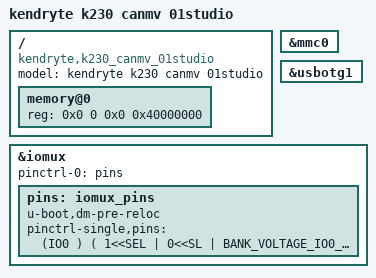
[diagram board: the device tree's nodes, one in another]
/* Copyright (c) 2023, Canaan Bright Sight Co., Ltd
 *
 * Redistribution and use in source and binary forms, with or without
 * modification, are permitted provided that the following conditions are met:
 * 1. Redistributions of source code must retain the above copyright
 * notice, this list of conditions and the following disclaimer.
 * 2. Redistributions in binary form must reproduce the above copyright
 * notice, this list of conditions and the following disclaimer in the
 * documentation and/or other materials provided with the distribution.
 *
 * THIS SOFTWARE IS PROVIDED BY THE COPYRIGHT HOLDERS AND
 * CONTRIBUTORS "AS IS" AND ANY EXPRESS OR IMPLIED WARRANTIES,
 * INCLUDING, BUT NOT LIMITED TO, THE IMPLIED WARRANTIES OF
 * MERCHANTABILITY AND FITNESS FOR A PARTICULAR PURPOSE ARE
 * DISCLAIMED. IN NO EVENT SHALL THE COPYRIGHT HOLDER OR
 * CONTRIBUTORS BE LIABLE FOR ANY DIRECT, INDIRECT, INCIDENTAL,
 * SPECIAL, EXEMPLARY, OR CONSEQUENTIAL DAMAGES (INCLUDING,
 * BUT NOT LIMITED TO, PROCUREMENT OF SUBSTITUTE GOODS OR
 * SERVICES; LOSS OF USE, DATA, OR PROFITS; OR BUSINESS
 * INTERRUPTION) HOWEVER CAUSED AND ON ANY THEORY OF LIABILITY,
 * WHETHER IN CONTRACT, STRICT LIABILITY, OR TORT (INCLUDING
 * NEGLIGENCE OR OTHERWISE) ARISING IN ANY WAY OUT OF THE USE
 * OF THIS SOFTWARE, EVEN IF ADVISED OF THE POSSIBILITY OF SUCH DAMAGE.
 */
/dts-v1/;
#include <dt-bindings/pinctrl/k230_evb.h>
#define BANK_VOLTAGE_IO0_IO1	 K230_MSC_1V8  /* fixed 1.8 V */
#define BANK_VOLTAGE_IO2_IO13	 K230_MSC_3V3  /* VDDIO_BANK0 */
#define BANK_VOLTAGE_IO14_IO25	 K230_MSC_1V8  /* VDDIO_BANK1 */
#define BANK_VOLTAGE_IO26_IO37	 K230_MSC_1V8  /* VDDIO_BANK2 */
#define BANK_VOLTAGE_IO38_IO49	 K230_MSC_3V3  /* VDDIO_BANK3 */
#define BANK_VOLTAGE_IO50_IO61	 K230_MSC_3V3  /* VDDIO_BANK4 */
#define BANK_VOLTAGE_IO62_IO63	 K230_MSC_1V8  /* VDDIO_BANK5 */
#include "k230.dtsi"

/ {
	model = "kendryte k230 canmv 01studio";
	compatible = "kendryte,k230_canmv_01studio";

	memory@0 {
		device_type = "memory";
		reg = <
				0x0 0 0x0 0x40000000
			  >;
	};
};

&mmc0 {
	status = "okay";
};
&usbotg1 {
	status = "okay";
};
&iomux {
	pinctrl-names = "default";
	pinctrl-0 = <&pins>;

	/*
	 * These voltage selections must match the board rails above; a mismatch can
	 * damage the SoC.  Use drive level 7 for driven signals and level 0 where the
	 * output buffer is disabled.  The K230 adaptation guide uses level 7 as its
	 * general-purpose setting for the dual-voltage pads.
	 */
	pins: iomux_pins {
		u-boot,dm-pre-reloc;
		pinctrl-single,pins = <

		/* Boot-mode straps: BOOT0 is pulled low and BOOT1 high externally. */
		(IO0 ) ( 1<<SEL | 0<<SL | BANK_VOLTAGE_IO0_IO1 <<MSC | 1<<IE | 0<<OE | 0<<PU | 0<<PD | 0<<DS | 1<<ST )
		(IO1 ) ( 1<<SEL | 0<<SL | BANK_VOLTAGE_IO0_IO1 <<MSC | 1<<IE | 0<<OE | 0<<PU | 0<<PD | 0<<DS | 1<<ST )

		/* IO2-IO8: unconnected; leave as high-impedance GPIOs. */
		(IO2 ) ( 0<<SEL | 0<<SL | BANK_VOLTAGE_IO2_IO13 <<MSC | 0<<IE | 0<<OE | 0<<PU | 0<<PD | 0<<DS | 0<<ST )
		(IO3 ) ( 0<<SEL | 0<<SL | BANK_VOLTAGE_IO2_IO13 <<MSC | 0<<IE | 0<<OE | 0<<PU | 0<<PD | 0<<DS | 0<<ST )
		(IO4 ) ( 0<<SEL | 0<<SL | BANK_VOLTAGE_IO2_IO13 <<MSC | 0<<IE | 0<<OE | 0<<PU | 0<<PD | 0<<DS | 0<<ST )
		(IO5 ) ( 0<<SEL | 0<<SL | BANK_VOLTAGE_IO2_IO13 <<MSC | 0<<IE | 0<<OE | 0<<PU | 0<<PD | 0<<DS | 0<<ST )
		(IO6 ) ( 0<<SEL | 0<<SL | BANK_VOLTAGE_IO2_IO13 <<MSC | 0<<IE | 0<<OE | 0<<PU | 0<<PD | 0<<DS | 0<<ST )
		(IO7 ) ( 0<<SEL | 0<<SL | BANK_VOLTAGE_IO2_IO13 <<MSC | 0<<IE | 0<<OE | 0<<PU | 0<<PD | 0<<DS | 0<<ST )
		(IO8 ) ( 0<<SEL | 0<<SL | BANK_VOLTAGE_IO2_IO13 <<MSC | 0<<IE | 0<<OE | 0<<PU | 0<<PD | 0<<DS | 0<<ST )

		/* Status LED, active high. */
		(IO9 ) ( 0<<SEL | 0<<SL | BANK_VOLTAGE_IO2_IO13 <<MSC | 0<<IE | 1<<OE | 0<<PU | 0<<PD | 7<<DS | 0<<ST )
		/* IO10: unconnected. */
		(IO10) ( 0<<SEL | 0<<SL | BANK_VOLTAGE_IO2_IO13 <<MSC | 0<<IE | 0<<OE | 0<<PU | 0<<PD | 0<<DS | 0<<ST )
		/* UART2 on the K230 GPIO interface header. */
		(IO11) ( 2<<SEL | 0<<SL | BANK_VOLTAGE_IO2_IO13 <<MSC | 0<<IE | 1<<OE | 0<<PU | 0<<PD | 7<<DS | 0<<ST ) /* K230_TX2 */
		(IO12) ( 2<<SEL | 0<<SL | BANK_VOLTAGE_IO2_IO13 <<MSC | 1<<IE | 0<<OE | 0<<PU | 0<<PD | 0<<DS | 1<<ST ) /* K230_RX2 */
		/* IO13: unconnected. */
		(IO13) ( 0<<SEL | 0<<SL | BANK_VOLTAGE_IO2_IO13 <<MSC | 0<<IE | 0<<OE | 0<<PU | 0<<PD | 0<<DS | 0<<ST )

		/* SPI0/OSPI drives the Sharp display through the TMUX1574 switch. */
		(IO14) ( 0<<SEL | 0<<SL | BANK_VOLTAGE_IO14_IO25<<MSC | 0<<IE | 1<<OE | 1<<PU | 0<<PD | 7<<DS | 0<<ST ) /* GPIO chip select: K230_SPI0_CS0 */
		(IO15) ( 1<<SEL | 0<<SL | BANK_VOLTAGE_IO14_IO25<<MSC | 0<<IE | 1<<OE | 0<<PU | 0<<PD | 7<<DS | 0<<ST ) /* OSPI_CLK: K230_SPI0_SCLK */
		(IO16) ( 1<<SEL | 0<<SL | BANK_VOLTAGE_IO14_IO25<<MSC | 0<<IE | 1<<OE | 0<<PU | 0<<PD | 7<<DS | 0<<ST ) /* OSPI_D0: K230_SPI0_MOSI */
		/* IO17-IO18: unconnected. */
		(IO17) ( 0<<SEL | 0<<SL | BANK_VOLTAGE_IO14_IO25<<MSC | 0<<IE | 0<<OE | 0<<PU | 0<<PD | 0<<DS | 0<<ST )
		(IO18) ( 0<<SEL | 0<<SL | BANK_VOLTAGE_IO14_IO25<<MSC | 0<<IE | 0<<OE | 0<<PU | 0<<PD | 0<<DS | 0<<ST )
		/* Sharp display DISP signal through the TMUX1574 switch. */
		(IO19) ( 0<<SEL | 0<<SL | BANK_VOLTAGE_IO14_IO25<<MSC | 0<<IE | 1<<OE | 0<<PU | 0<<PD | 7<<DS | 0<<ST ) /* K230_DISP_DISP */

		/*
		 * QSPI1 link to the nRF52840.  Both pad directions are enabled so the
		 * controller role can be selected by software.
		 */
		(IO20) ( 2<<SEL | 0<<SL | BANK_VOLTAGE_IO14_IO25<<MSC | 1<<IE | 1<<OE | 1<<PU | 0<<PD | 7<<DS | 1<<ST ) /* K230_SPI1_CS0 */
		(IO21) ( 2<<SEL | 0<<SL | BANK_VOLTAGE_IO14_IO25<<MSC | 1<<IE | 1<<OE | 0<<PU | 0<<PD | 7<<DS | 1<<ST ) /* K230_SPI1_SCLK */
		(IO22) ( 2<<SEL | 0<<SL | BANK_VOLTAGE_IO14_IO25<<MSC | 1<<IE | 1<<OE | 0<<PU | 0<<PD | 7<<DS | 1<<ST ) /* K230_SPI1_MOSI / NRF_SPI1_MISO */
		(IO23) ( 2<<SEL | 0<<SL | BANK_VOLTAGE_IO14_IO25<<MSC | 1<<IE | 1<<OE | 0<<PU | 0<<PD | 7<<DS | 1<<ST ) /* K230_SPI1_MISO / NRF_SPI1_MOSI */
		/* IO24: unconnected. */
		(IO24) ( 0<<SEL | 0<<SL | BANK_VOLTAGE_IO14_IO25<<MSC | 0<<IE | 0<<OE | 0<<PU | 0<<PD | 0<<DS | 0<<ST )
		/* Pulled down until board code actively drives K230_STATUS low. */
		(IO25) ( 0<<SEL | 0<<SL | BANK_VOLTAGE_IO14_IO25<<MSC | 0<<IE | 1<<OE | 0<<PU | 1<<PD | 7<<DS | 0<<ST ) /* K230_STATUS */

		/* IO26-IO35: unconnected; leave as high-impedance GPIOs. */
		(IO26) ( 0<<SEL | 0<<SL | BANK_VOLTAGE_IO26_IO37<<MSC | 0<<IE | 0<<OE | 0<<PU | 0<<PD | 0<<DS | 0<<ST )
		(IO27) ( 0<<SEL | 0<<SL | BANK_VOLTAGE_IO26_IO37<<MSC | 0<<IE | 0<<OE | 0<<PU | 0<<PD | 0<<DS | 0<<ST )
		(IO28) ( 0<<SEL | 0<<SL | BANK_VOLTAGE_IO26_IO37<<MSC | 0<<IE | 0<<OE | 0<<PU | 0<<PD | 0<<DS | 0<<ST )
		(IO29) ( 0<<SEL | 0<<SL | BANK_VOLTAGE_IO26_IO37<<MSC | 0<<IE | 0<<OE | 0<<PU | 0<<PD | 0<<DS | 0<<ST )
		(IO30) ( 0<<SEL | 0<<SL | BANK_VOLTAGE_IO26_IO37<<MSC | 0<<IE | 0<<OE | 0<<PU | 0<<PD | 0<<DS | 0<<ST )
		(IO31) ( 0<<SEL | 0<<SL | BANK_VOLTAGE_IO26_IO37<<MSC | 0<<IE | 0<<OE | 0<<PU | 0<<PD | 0<<DS | 0<<ST )
		(IO32) ( 0<<SEL | 0<<SL | BANK_VOLTAGE_IO26_IO37<<MSC | 0<<IE | 0<<OE | 0<<PU | 0<<PD | 0<<DS | 0<<ST )
		(IO33) ( 0<<SEL | 0<<SL | BANK_VOLTAGE_IO26_IO37<<MSC | 0<<IE | 0<<OE | 0<<PU | 0<<PD | 0<<DS | 0<<ST )
		(IO34) ( 0<<SEL | 0<<SL | BANK_VOLTAGE_IO26_IO37<<MSC | 0<<IE | 0<<OE | 0<<PU | 0<<PD | 0<<DS | 0<<ST )
		(IO35) ( 0<<SEL | 0<<SL | BANK_VOLTAGE_IO26_IO37<<MSC | 0<<IE | 0<<OE | 0<<PU | 0<<PD | 0<<DS | 0<<ST )

		/* UART4 link to the nRF52840, through 1 kOhm series resistors. */
		(IO36) ( 3<<SEL | 0<<SL | BANK_VOLTAGE_IO26_IO37<<MSC | 0<<IE | 1<<OE | 0<<PU | 0<<PD | 7<<DS | 0<<ST ) /* K230_TX4 -> NRF_RX0 */
		(IO37) ( 3<<SEL | 0<<SL | BANK_VOLTAGE_IO26_IO37<<MSC | 1<<IE | 0<<OE | 0<<PU | 0<<PD | 0<<DS | 1<<ST ) /* K230_RX4 <- NRF_TX0 */

		/* UART0 channel of the CH342K USB-to-UART bridge. */
		(IO38) ( 1<<SEL | 0<<SL | BANK_VOLTAGE_IO38_IO49<<MSC | 0<<IE | 1<<OE | 0<<PU | 0<<PD | 7<<DS | 0<<ST ) /* K230_UART0_TXD */
		(IO39) ( 1<<SEL | 0<<SL | BANK_VOLTAGE_IO38_IO49<<MSC | 1<<IE | 0<<OE | 0<<PU | 0<<PD | 0<<DS | 1<<ST ) /* K230_UART0_RXD */

		/* UART1 link to the AIC8800D Bluetooth interface. */
		(IO40) ( 1<<SEL | 0<<SL | BANK_VOLTAGE_IO38_IO49<<MSC | 0<<IE | 1<<OE | 0<<PU | 0<<PD | 7<<DS | 0<<ST ) /* TXD -> BT-UART-RX */
		(IO41) ( 1<<SEL | 0<<SL | BANK_VOLTAGE_IO38_IO49<<MSC | 1<<IE | 0<<OE | 0<<PU | 0<<PD | 0<<DS | 1<<ST ) /* RXD <- BT-UART-TX */
		(IO42) ( 1<<SEL | 0<<SL | BANK_VOLTAGE_IO38_IO49<<MSC | 0<<IE | 1<<OE | 0<<PU | 0<<PD | 7<<DS | 0<<ST ) /* RTS -> BT-UART-CTS */
		(IO43) ( 1<<SEL | 0<<SL | BANK_VOLTAGE_IO38_IO49<<MSC | 1<<IE | 0<<OE | 0<<PU | 0<<PD | 0<<DS | 1<<ST ) /* CTS <- BT-UART-RTS */

		/* IO44-IO49: unconnected; leave as high-impedance GPIOs. */
		(IO44) ( 0<<SEL | 0<<SL | BANK_VOLTAGE_IO38_IO49<<MSC | 0<<IE | 0<<OE | 0<<PU | 0<<PD | 0<<DS | 0<<ST )
		(IO45) ( 0<<SEL | 0<<SL | BANK_VOLTAGE_IO38_IO49<<MSC | 0<<IE | 0<<OE | 0<<PU | 0<<PD | 0<<DS | 0<<ST )
		(IO46) ( 0<<SEL | 0<<SL | BANK_VOLTAGE_IO38_IO49<<MSC | 0<<IE | 0<<OE | 0<<PU | 0<<PD | 0<<DS | 0<<ST )
		(IO47) ( 0<<SEL | 0<<SL | BANK_VOLTAGE_IO38_IO49<<MSC | 0<<IE | 0<<OE | 0<<PU | 0<<PD | 0<<DS | 0<<ST )
		(IO48) ( 0<<SEL | 0<<SL | BANK_VOLTAGE_IO38_IO49<<MSC | 0<<IE | 0<<OE | 0<<PU | 0<<PD | 0<<DS | 0<<ST )
		(IO49) ( 0<<SEL | 0<<SL | BANK_VOLTAGE_IO38_IO49<<MSC | 0<<IE | 0<<OE | 0<<PU | 0<<PD | 0<<DS | 0<<ST )

		/* UART1 channel of the CH342K USB-to-UART bridge. */
		(IO50) ( 1<<SEL | 0<<SL | BANK_VOLTAGE_IO50_IO61<<MSC | 0<<IE | 1<<OE | 0<<PU | 0<<PD | 7<<DS | 0<<ST ) /* K230_UART3_TXD */
		(IO51) ( 1<<SEL | 0<<SL | BANK_VOLTAGE_IO50_IO61<<MSC | 1<<IE | 0<<OE | 0<<PU | 0<<PD | 0<<DS | 1<<ST ) /* K230_UART3_RXD */

		/* AIC8800D reset and Wi-Fi enable controls. */
		(IO52) ( 0<<SEL | 0<<SL | BANK_VOLTAGE_IO50_IO61<<MSC | 0<<IE | 1<<OE | 0<<PU | 0<<PD | 7<<DS | 0<<ST ) /* BT-RESETN */
		(IO53) ( 0<<SEL | 0<<SL | BANK_VOLTAGE_IO50_IO61<<MSC | 0<<IE | 1<<OE | 0<<PU | 0<<PD | 7<<DS | 0<<ST ) /* WIFI_REGON */

		/* MMC1/SDIO link to the AIC8800D Wi-Fi interface. */
		(IO54) ( 2<<SEL | 0<<SL | BANK_VOLTAGE_IO50_IO61<<MSC | 1<<IE | 1<<OE | 1<<PU | 0<<PD | 7<<DS | 1<<ST ) /* WIFI_CMD */
		(IO55) ( 2<<SEL | 0<<SL | BANK_VOLTAGE_IO50_IO61<<MSC | 0<<IE | 1<<OE | 0<<PU | 0<<PD | 7<<DS | 0<<ST ) /* WIFI_CLK */
		(IO56) ( 2<<SEL | 0<<SL | BANK_VOLTAGE_IO50_IO61<<MSC | 1<<IE | 1<<OE | 1<<PU | 0<<PD | 7<<DS | 1<<ST ) /* WIFI_D0 */
		(IO57) ( 2<<SEL | 0<<SL | BANK_VOLTAGE_IO50_IO61<<MSC | 1<<IE | 1<<OE | 1<<PU | 0<<PD | 7<<DS | 1<<ST ) /* WIFI_D1 */
		(IO58) ( 2<<SEL | 0<<SL | BANK_VOLTAGE_IO50_IO61<<MSC | 1<<IE | 1<<OE | 1<<PU | 0<<PD | 7<<DS | 1<<ST ) /* WIFI_D2 */
		(IO59) ( 2<<SEL | 0<<SL | BANK_VOLTAGE_IO50_IO61<<MSC | 1<<IE | 1<<OE | 1<<PU | 0<<PD | 7<<DS | 1<<ST ) /* WIFI_D3 */

		/* IO60-IO63: unconnected; leave as high-impedance GPIOs. */
		(IO60) ( 0<<SEL | 0<<SL | BANK_VOLTAGE_IO50_IO61<<MSC | 0<<IE | 0<<OE | 0<<PU | 0<<PD | 0<<DS | 0<<ST )
		(IO61) ( 0<<SEL | 0<<SL | BANK_VOLTAGE_IO50_IO61<<MSC | 0<<IE | 0<<OE | 0<<PU | 0<<PD | 0<<DS | 0<<ST )
		(IO62) ( 0<<SEL | 0<<SL | BANK_VOLTAGE_IO62_IO63<<MSC | 0<<IE | 0<<OE | 0<<PU | 0<<PD | 0<<DS | 0<<ST )
		(IO63) ( 0<<SEL | 0<<SL | BANK_VOLTAGE_IO62_IO63<<MSC | 0<<IE | 0<<OE | 0<<PU | 0<<PD | 0<<DS | 0<<ST )
		>;
	};
};
